# max32655 register map
Vendor: Maxim-Integrated; Series: ARMCM4; File version: 1.1
CPU: CM4 r2p1, little endian, MPU, FPU, 3 interrupt priority bits
Registers are 32-bit, read-write, reset 0x0 unless marked. A register's access mark holds for its fields unless they carry their own. Offsets are from the block's base; [hi:lo] are bit positions; 'fields as' and 'values as' point back to an identical list.

## SIMO — Single Inductor Multiple Output Switching Converter
Base 0x40004400
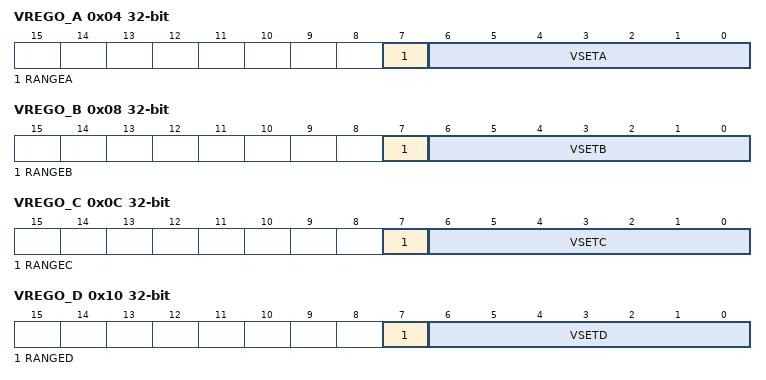
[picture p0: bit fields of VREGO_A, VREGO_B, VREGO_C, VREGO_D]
0x04 VREGO_A — Buck Voltage Regulator A Control Register
  [7] RANGEA — Regulator Output Range Set
    0=low (Low output voltage range); 1=High output voltage range
  [6:0] VSETA — Regulator Output Voltage Setting
0x08 VREGO_B — Buck Voltage Regulator B Control Register
  [7] RANGEB — Regulator Output Range Set
    values as VREGO_A.RANGEA
  [6:0] VSETB — Regulator Output Voltage Setting
0x0C VREGO_C — Buck Voltage Regulator C Control Register
  [7] RANGEC — Regulator Output Range Set
    values as VREGO_A.RANGEA
  [6:0] VSETC — Regulator Output Voltage Setting
0x10 VREGO_D — Buck Voltage Regulator D Control Register
  [7] RANGED — Regulator Output Range Set
    values as VREGO_A.RANGEA
  [6:0] VSETD — Regulator Output Voltage Setting
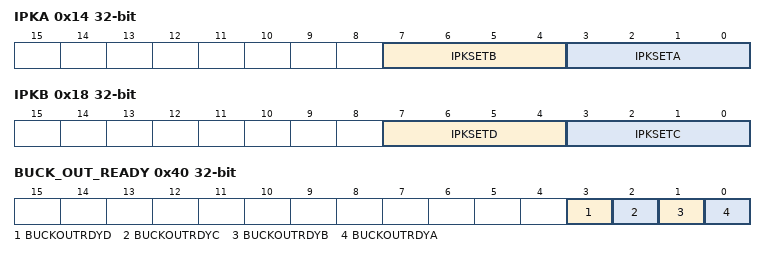
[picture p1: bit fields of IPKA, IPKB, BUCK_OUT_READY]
0x14 IPKA — High Side FET Peak Current VREGO_A/VREGO_B Register
  [7:4] IPKSETB — Voltage Regulator Peak Current Setting
  [3:0] IPKSETA — Voltage Regulator Peak Current Setting
0x18 IPKB — High Side FET Peak Current VREGO_C/VREGO_D Register
  [7:4] IPKSETD — Voltage Regulator Peak Current Setting
  [3:0] IPKSETC — Voltage Regulator Peak Current Setting
0x1C MAXTON — Maximum High Side FET Time On Register
  [3:0] TONSET — Sets the maximum on time for the high side FET, each increment represents 500ns
0x20 ILOAD_A ro — Buck Cycle Count VREGO_A Register
  [7:0] ILOADA — Number of buck cycles that occur within the cycle clock
0x24 ILOAD_B ro — Buck Cycle Count VREGO_B Register
  [7:0] ILOADB — Number of buck cycles that occur within the cycle clock
0x28 ILOAD_C ro — Buck Cycle Count VREGO_C Register
  [7:0] ILOADC — Number of buck cycles that occur within the cycle clock
0x2C ILOAD_D ro — Buck Cycle Count VREGO_D Register
  [7:0] ILOADD — Number of buck cycles that occur within the cycle clock
0x30 BUCK_ALERT_THR_A — Buck Cycle Count Alert VERGO_A Register
  [7:0] BUCKTHRA — Threshold for ILOADA to generate the BUCK_ALERT
0x34 BUCK_ALERT_THR_B — Buck Cycle Count Alert VERGO_B Register
  [7:0] BUCKTHRB — Threshold for ILOADB to generate the BUCK_ALERT
0x38 BUCK_ALERT_THR_C — Buck Cycle Count Alert VERGO_C Register
  [7:0] BUCKTHRC — Threshold for ILOADC to generate the BUCK_ALERT
0x3C BUCK_ALERT_THR_D — Buck Cycle Count Alert VERGO_D Register
  [7:0] BUCKTHRD — Threshold for ILOADD to generate the BUCK_ALERT
0x40 BUCK_OUT_READY ro — Buck Regulator Output Ready Register
  [all] fields
    0=notrdy (Output voltage not in range); 1=rdy (Output voltage in range)
  [3] BUCKOUTRDYD — When set, indicates that the output voltage has reached its regulated value
  [2] BUCKOUTRDYC — When set, indicates that the output voltage has reached its regulated value
  [1] BUCKOUTRDYB — When set, indicates that the output voltage has reached its regulated value
  [0] BUCKOUTRDYA — When set, indicates that the output voltage has reached its regulated value
0x44 ZERO_CROSS_CAL_A ro — Zero Cross Calibration VERGO_A Register
  [3:0] ZXCALA — Zero Cross Calibrartion Value VREGO_A
0x48 ZERO_CROSS_CAL_B ro — Zero Cross Calibration VERGO_B Register
  [3:0] ZXCALB — Zero Cross Calibrartion Value VREGO_B
0x4C ZERO_CROSS_CAL_C ro — Zero Cross Calibration VERGO_C Register
  [3:0] ZXCALC — Zero Cross Calibrartion Value VREGO_C
0x50 ZERO_CROSS_CAL_D ro — Zero Cross Calibration VERGO_D Register
  [3:0] ZXCALD — Zero Cross Calibrartion Value VREGO_D

## SIR — System Initialization Registers.
Base 0x40000400
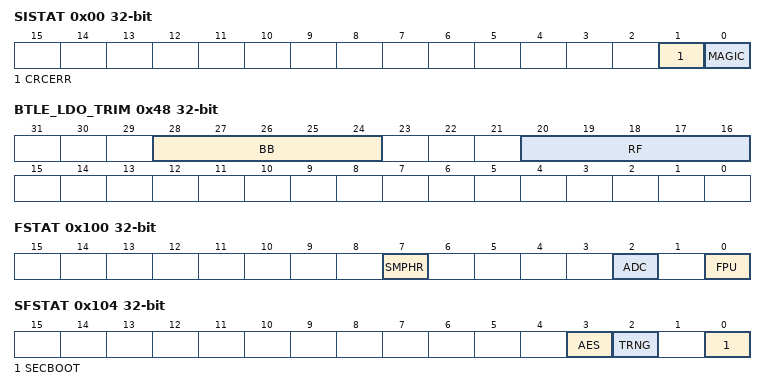
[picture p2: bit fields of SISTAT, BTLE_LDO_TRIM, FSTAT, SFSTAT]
0x00 SISTAT ro — System Initialization Status Register.
  [1] CRCERR — CRC Error Status. This bit is set by the system initialization block following power-up.
    on read: 0=noError (No CRC errors occurred during the read of the OTP memory block.); 1=error (A CRC error occurred while reading the OTP. The address of the failure location in the OTP memory is stored in the ERRADDR register.)
  [0] MAGIC — Magic Word Validation. This bit is set by the system initialization block following power-up.
    on read: 0=magicNotSet (Magic word was not set (OTP has not been initialized properly).); 1=magicSet (Magic word was set (OTP contains valid settings).)
0x04 ADDR ro — Read-only field set by the SIB block if a CRC error occurs during the read of the OTP memory. Contains the failing address in OTP memory (when CRCERR equals 1).
  [31:0] ERRADDR
0x48 BTLE_LDO_TRIM
  [28:24] BB — BB LDO trim value.
  [20:16] RF — RF LDO trim value.
0x100 FSTAT ro — funcstat register.
  [all] fields
    0=no; 1=yes
  [7] SMPHR — SMPHR function.
  [2] ADC — 10-bit Sigma Delta ADC.
  [0] FPU — FPU Function.
0x104 SFSTAT ro — Security function status register.
  [3] AES — AES Block.
    0=no; 1=yes
  [2] TRNG — TRNG Function.
    0=no; 1=yes
  [0] SECBOOT — Security Boot.
